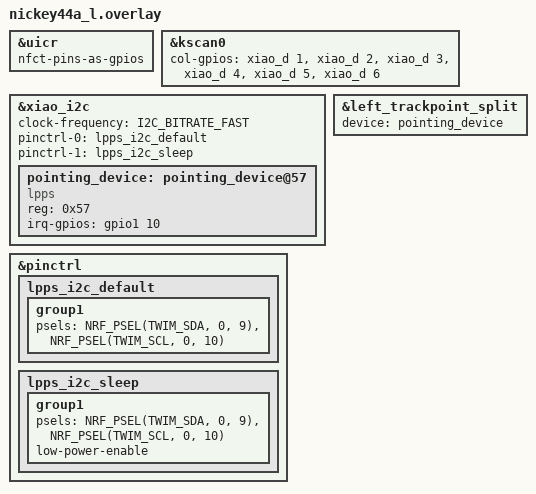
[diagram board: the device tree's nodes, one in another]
#include <zephyr/dt-bindings/i2c/i2c.h>
#include <zephyr/dt-bindings/pinctrl/nrf-pinctrl.h>

#include "nickey44a.dtsi"

&uicr {
    nfct-pins-as-gpios;
};

&kscan0 {
        col-gpios
            = <&xiao_d 1 GPIO_ACTIVE_HIGH>
            , <&xiao_d 2 GPIO_ACTIVE_HIGH>
            , <&xiao_d 3 GPIO_ACTIVE_HIGH>
            , <&xiao_d 4 GPIO_ACTIVE_HIGH>
            , <&xiao_d 5 GPIO_ACTIVE_HIGH>
            , <&xiao_d 6 GPIO_ACTIVE_HIGH>
            ;
};

&xiao_i2c {
    status = "okay";
    clock-frequency = <I2C_BITRATE_FAST>;
    pinctrl-0 = <&lpps_i2c_default>;
    pinctrl-1 = <&lpps_i2c_sleep>;
    pinctrl-names = "default", "sleep";

    pointing_device: pointing_device@57 {
        compatible = "lpps";
        reg = <0x57>;
        irq-gpios = <&gpio1 10 GPIO_PULL_UP>;
        status = "okay";
    };
};

&left_trackpoint_split {
    device = <&pointing_device>;
};

&pinctrl {
    lpps_i2c_default: lpps_i2c_default {
        group1 {
            psels = <NRF_PSEL(TWIM_SDA, 0, 9)>,
                    <NRF_PSEL(TWIM_SCL, 0, 10)>;
        };
    };

    lpps_i2c_sleep: lpps_i2c_sleep {
        group1 {
            psels = <NRF_PSEL(TWIM_SDA, 0, 9)>,
                    <NRF_PSEL(TWIM_SCL, 0, 10)>;
            low-power-enable;
        };
    };
};
